# STM32U575xx register map
File version: 1.0
Registers are 32-bit, read-write, reset 0x0 unless marked. A register's access mark holds for its fields unless they carry their own. Offsets are from the block's base; [hi:lo] are bit positions; {n}, {i} and the like mark numbered series.

## GTZC_MPCBB1
Base 0x40032C00
Same registers: GTZC_MPCBB2 0x40033000, GTZC_MPCBB3 0x40033400, GTZC_MPCBB4 0x46023800, GTZC_MPCBB1_S 0x50032C00, GTZC_MPCBB2_S 0x50033000, GTZC_MPCBB3_S 0x50033400, GTZC_MPCBB4_S 0x56023800
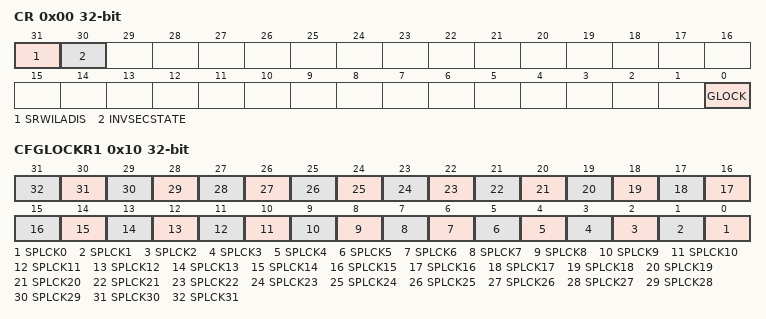
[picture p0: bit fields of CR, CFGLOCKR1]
0x00 CR — MPCBBx control register
  [31] SRWILADIS, [30] INVSECSTATE, [0] GLOCK
0x10 CFGLOCKR1 — MPCBBx Configuration lock register
  [n] SPLCK{n} (n=0..31)
{0x100+4i} SECCFGR{i} (i=0..31) — MPCBBx security configuration registers
{0x200+4i} PRIVCFGR{i} (i=0..31) — MPCBBx privilege configuration registers

## GPIOA — General Purpose I/O
Base 0x42020000
Same registers: GPIOB 0x42020400, GPIOC 0x42020800, GPIOD 0x42020C00, GPIOE 0x42021000, GPIOF 0x42021400, GPIOG 0x42021800, GPIOH 0x42021C00, GPIOI 0x42022000, GPIOA_S 0x52020000, GPIOB_S 0x52020400, GPIOC_S 0x52020800, GPIOD_S 0x52020C00, GPIOE_S 0x52021000, GPIOF_S 0x52021400, GPIOG_S 0x52021800, GPIOH_S 0x52021C00, GPIOI_S 0x52022000
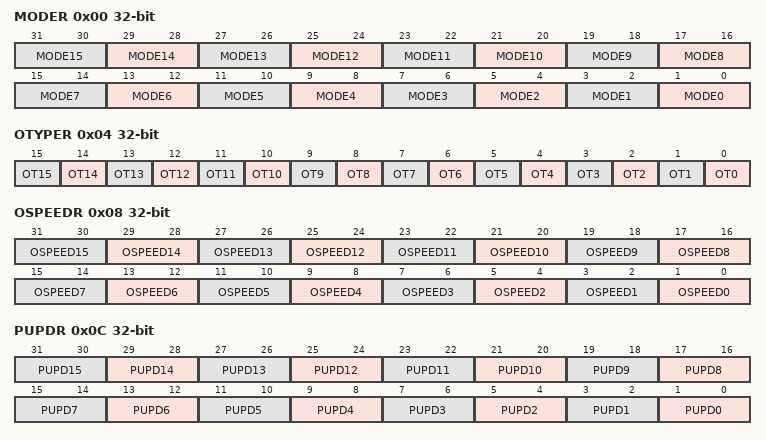
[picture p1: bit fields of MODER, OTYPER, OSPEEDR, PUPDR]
0x00 MODER — GPIO port mode register
  [2n+1:2n] MODE{n} (n=0..15)
0x04 OTYPER — GPIO port output type register
  [n] OT{n} (n=0..15)
0x08 OSPEEDR — GPIO port output speed register
  [2n+1:2n] OSPEED{n} (n=0..15)
0x0C PUPDR — GPIO port pull-up/pull-down register
  [2n+1:2n] PUPD{n} (n=0..15)
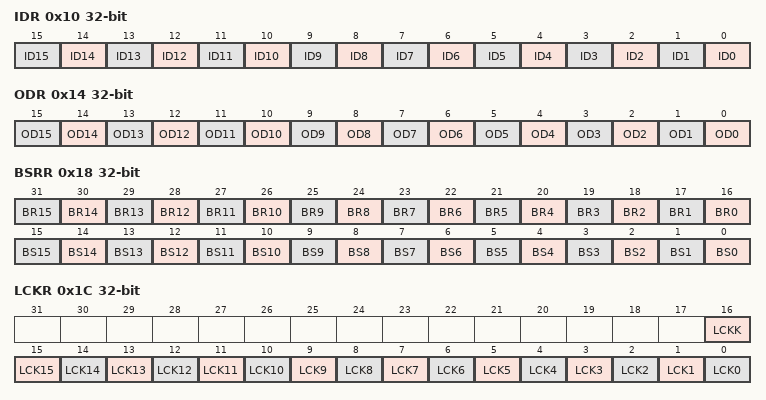
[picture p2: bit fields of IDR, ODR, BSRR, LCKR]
0x10 IDR — GPIO port input data register
  [n] ID{n} (n=0..15)
0x14 ODR — GPIO port output data register
  [n] OD{n} (n=0..15)
0x18 BSRR — GPIO port bit set/reset register
  [n+16] BR{n} (n=0..15), [n] BS{n} (n=0..15)
0x1C LCKR — GPIO port configuration lock register
  [16] LCKK, [n] LCK{n} (n=0..15)
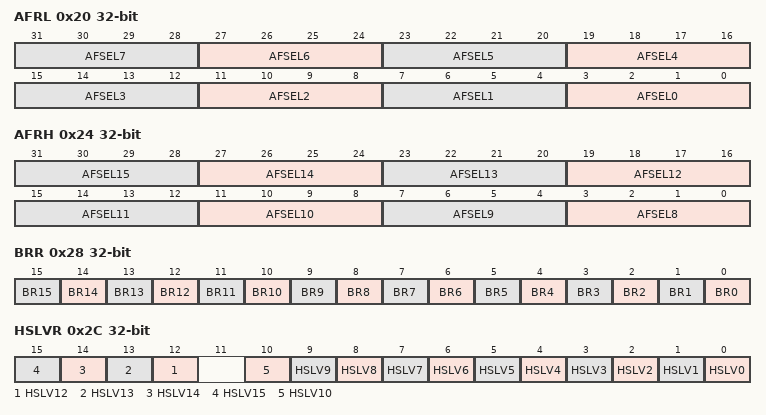
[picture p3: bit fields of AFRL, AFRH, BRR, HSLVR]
0x20 AFRL — GPIO alternate function registers
  [4n+3:4n] AFSEL{n} (n=0..7)
0x24 AFRH — GPIO alternate function registers
  [4n-29:4n-32] AFSEL{n} (n=8..15)
0x28 BRR — GPIO Bit Reset register
  [n] BR{n} (n=0..15)
0x2C HSLVR — GPIO high-speed low voltage register
  [n] HSLV{n} (n=12..15), [n] HSLV{n} (n=0..10)
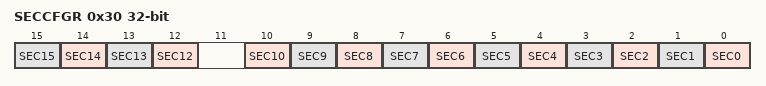
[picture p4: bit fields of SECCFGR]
0x30 SECCFGR — GPIO secure configuration register
  [n] SEC{n} (n=12..15), [n] SEC{n} (n=0..10)

## LPGPIO1 — General Purpose I/O
Base 0x46020000
Same registers: LPGPIO1_S 0x56020000
Registers as GPIOA; these are added or differ:
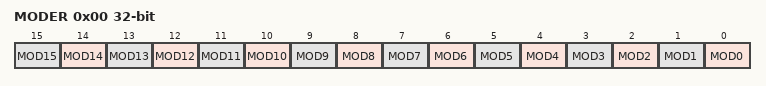
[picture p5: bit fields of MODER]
0x00 MODER — GPIO port mode register
  [n] MOD{n} (n=0..15)

## ADC12_COMMON
Base 0x42028308
Same registers: ADC12_COMMON_S 0x52028308
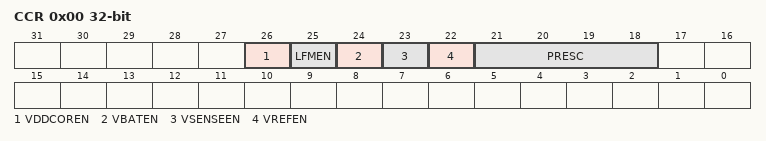
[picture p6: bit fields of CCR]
0x00 CCR — ADC common control register
  [26] VDDCOREN — VDDCode enable
  [25] LFMEN — Low Frequency Mode Enable, specific ADC4
  [24] VBATEN — VBAT enable
  [23] VSENSEEN — Temperature sensor enable
  [22] VREFEN — VREFINT enable
  [21:18] PRESC — ADC prescaler
    0=DIV1; 1=DIV2; 2=DIV4; 3=DIV6; 4=DIV8; 5=DIV10; 6=DIV12; 7=DIV16; 8=DIV32; 9=DIV64; 10=DIV128; 11=DIV256

## DCMI
Base 0x4202C000
Same registers: DCMI_S 0x5202C000
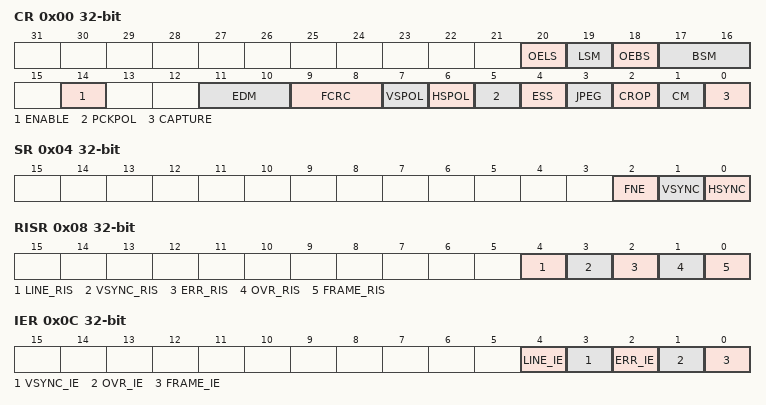
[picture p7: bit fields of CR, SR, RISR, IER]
0x00 CR — DCMI control register 1
  [20] OELS
  [19] LSM
  [18] OEBS
  [17:16] BSM
  [14] ENABLE
  [11:10] EDM — DCMI Extended data mode EDM[1:0]
  [9:8] FCRC — DCMI Frame capture rate control FCRC[1:0]
  [7] VSPOL
  [6] HSPOL
  [5] PCKPOL
  [4] ESS
  [3] JPEG
  [2] CROP
  [1] CM
  [0] CAPTURE
0x04 SR — DCMI status register
  [2] FNE, [1] VSYNC, [0] HSYNC
0x08 RISR — DCMI raw interrupt status register
  [4] LINE_RIS, [3] VSYNC_RIS, [2] ERR_RIS, [1] OVR_RIS, [0] FRAME_RIS
0x0C IER — DCMI interrupt enable register
  [4] LINE_IE, [3] VSYNC_IE, [2] ERR_IE, [1] OVR_IE, [0] FRAME_IE
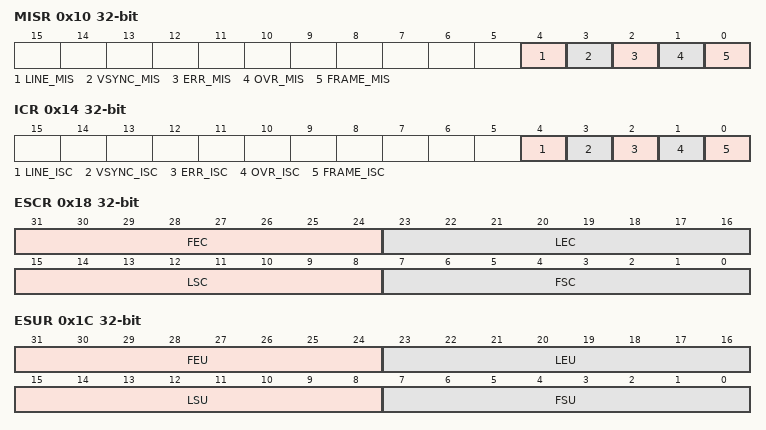
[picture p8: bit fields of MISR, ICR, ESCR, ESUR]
0x10 MISR — DCMI masked interrupt status register
  [4] LINE_MIS, [3] VSYNC_MIS, [2] ERR_MIS, [1] OVR_MIS, [0] FRAME_MIS
0x14 ICR — DCMI interrupt clear register
  [4] LINE_ISC, [3] VSYNC_ISC, [2] ERR_ISC, [1] OVR_ISC, [0] FRAME_ISC
0x18 ESCR — DCMI embedded synchronization code register
  [31:24] FEC, [23:16] LEC, [15:8] LSC, [7:0] FSC
0x1C ESUR — DCMI embedded synchronization unmask register
  [31:24] FEU, [23:16] LEU, [15:8] LSU, [7:0] FSU
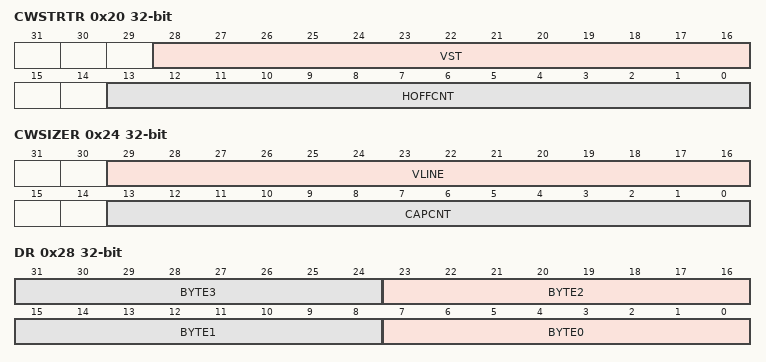
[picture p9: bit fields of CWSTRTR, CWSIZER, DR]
0x20 CWSTRTR — DCMI crop window start
  [28:16] VST, [13:0] HOFFCNT
0x24 CWSIZER — DCMI crop window size
  [29:16] VLINE, [13:0] CAPCNT
0x28 DR — DCMI data register
  [8n+7:8n] BYTE{n} (n=0..3)
